# ESP32-H4 register map
Vendor: ESPRESSIF SYSTEMS (SHANGHAI) CO., LTD.; Series: ESP32 H-Series; File version: 1
CPU: RV32IMAC r0p0, little endian, no MPU, no FPU, 0 interrupt priority bits
Address unit: 32 bits
Registers are 32-bit, read-write, reset 0x0 unless marked. A register's access mark holds for its fields unless they carry their own. Offsets are from the block's base; [hi:lo] are bit positions; {n}, {i} and the like mark numbered series.

## HUK — HUK Peripheral
Base 0x600B1000
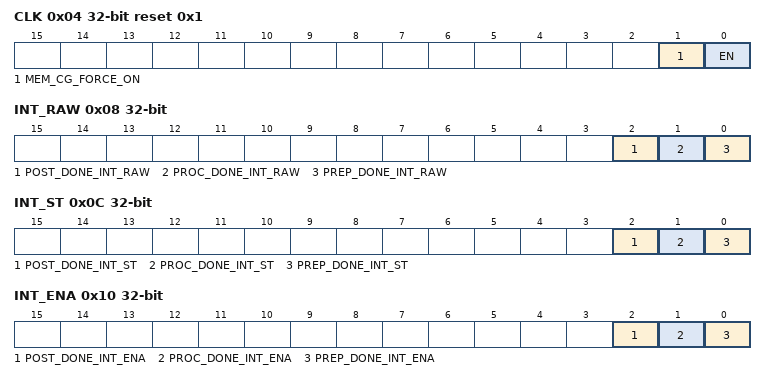
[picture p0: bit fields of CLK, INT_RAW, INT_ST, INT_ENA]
0x04 CLK reset 0x1 — HUK Generator clock gate control register
  [1] MEM_CG_FORCE_ON — Write 1 to force on memory clock gate.
  [0] EN — Write 1 to force on register clock gate.
0x08 INT_RAW ro — HUK Generator interrupt raw register, valid in level.
  [2] POST_DONE_INT_RAW — The raw interrupt status bit for the huk_post_done_int interrupt
  [1] PROC_DONE_INT_RAW — The raw interrupt status bit for the huk_proc_done_int interrupt
  [0] PREP_DONE_INT_RAW — The raw interrupt status bit for the huk_prep_done_int interrupt
0x0C INT_ST ro — HUK Generator interrupt status register.
  [2] POST_DONE_INT_ST — The masked interrupt status bit for the huk_post_done_int interrupt
  [1] PROC_DONE_INT_ST — The masked interrupt status bit for the huk_proc_done_int interrupt
  [0] PREP_DONE_INT_ST — The masked interrupt status bit for the huk_prep_done_int interrupt
0x10 INT_ENA — HUK Generator interrupt enable register.
  [2] POST_DONE_INT_ENA — The interrupt enable bit for the huk_post_done_int interrupt
  [1] PROC_DONE_INT_ENA — The interrupt enable bit for the huk_proc_done_int interrupt
  [0] PREP_DONE_INT_ENA — The interrupt enable bit for the huk_prep_done_int interrupt
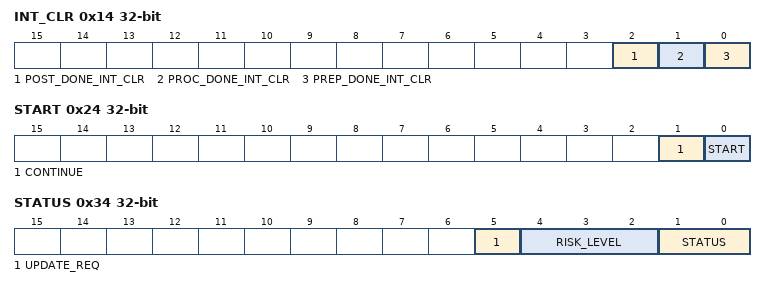
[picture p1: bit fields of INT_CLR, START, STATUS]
0x14 INT_CLR wo — HUK Generator interrupt clear register.
  [2] POST_DONE_INT_CLR — Set this bit to clear the huk_post_done_int interrupt
  [1] PROC_DONE_INT_CLR — Set this bit to clear the huk_proc_done_int interrupt
  [0] PREP_DONE_INT_CLR — Set this bit to clear the huk_prep_done_int interrupt
0x20 CONF — HUK Generator configuration register
  [0] MODE — Set this field to choose the huk process. 1: process huk generate mode. 0: process huk recovery mode.
0x24 START wo — HUK Generator control register
  [1] CONTINUE — Write 1 to start HUK Generator at IDLE state.
  [0] START — Write 1 to continue HUK Generator operation at LOAD/GAIN state.
0x28 STATE ro — HUK Generator state register
  [1:0] STATE — The state of HUK Generator. 0: IDLE. 1: LOAD. 2: GAIN. 3: BUSY.
0x34 STATUS ro — HUK Generator HUK status register
  [5] UPDATE_REQ — The update request of HUK info. 0: User can update HUK info according to the risk level. 1: The HUK info is expired, and user need to update it.
  [4:2] RISK_LEVEL — The risk level of HUK. 0-6: the higher the risk level is, the more error bits there are in the PUF SRAM. 7: Error Level, HUK is invalid.
  [1:0] STATUS — The HUK generation status. 0: HUK is not generated. 1: HUK is generated and valid. 2: HUK is generated but invalid. 3: reserved.
0xFC DATE reset 0x2404070 — Version control register
  [27:0] DATE — HUK Generator version control register.
{0x100+i} INFO_MEM[{i}] (i=0..383) 8-bit access not given — The memory that stores HUK info.

## INTPRI — INTPRI Peripheral
Base 0x60005000
{0x90+4i} CPU_INTR_FROM_CPU_{i} (i=0..3) — CPU_INTR_FROM_CPU_{i} mapping register
  [0] CPU_INTR_FROM_CPU — CPU_INTR_FROM_CPU_%s mapping register.
0xA0 DATE reset 0x2303150 — Version control register
  [27:0] DATE — Version control register.
0xA4 CLOCK_GATE reset 0x1 — register description
  [0] CLK_EN — Need add description
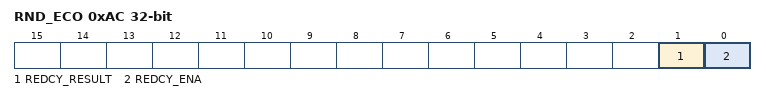
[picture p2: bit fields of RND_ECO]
0xAC RND_ECO access per field — redcy eco register.
  [1] REDCY_RESULT ro — Only reserved for ECO.
  [0] REDCY_ENA rw — Only reserved for ECO.
0xB0 RND_ECO_LOW — redcy eco low register.
  [31:0] REDCY_LOW — Only reserved for ECO.
0x3FC RND_ECO_HIGH reset 0xFFFFFFFF — redcy eco high register.
  [31:0] REDCY_HIGH — Only reserved for ECO.

## IO_MUX — Input/Output Multiplexer
Base 0x60092000
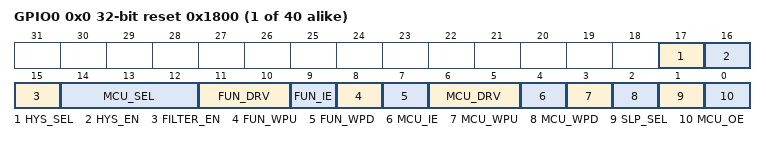
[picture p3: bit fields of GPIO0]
{0x0+4i} GPIO{i} (i=0..39) reset 0x1800 — IO MUX configuration register for GPIO{i}
  [17] HYS_SEL — Configures to choose the signal for enabling the hysteresis function for GPIO%s. \\ 0: Choose the output enable signal of eFuse\\ 1: Choose the output enable signal of IO_MUX_GPIO%s_HYS_EN\\
  [16] HYS_EN — Configures whether or not to enable the hysteresis function of the pin when IO_MUX_GPIO%s_HYS_SEL is set to 1.\\ 0: Disable\\ 1: Enable\\
  [15] FILTER_EN — Configures whether or not to enable filter for pin input signals.\\ 0: Disable\\ 1: Enable\\
  [14:12] MCU_SEL — Configures to select IO MUX function for this signal. \\ 0: Select Function 0\\ 1: Select Function 1\\ ......\\
  [11:10] FUN_DRV — Configures the drive strength of GPIO%s. \\ 0: ~5 mA\\ 1: ~10 mA\\ 2: ~20 mA\\ 3: ~40 mA\\
  [9] FUN_IE — Configures whether or not to enable input of GPIO%s.\\ 0: Disable\\ 1: Enable\\
  [8] FUN_WPU — Configures whether or not enable pull-up resistor of GPIO%s.\\ 0: Disable\\ 1: Enable\\
  [7] FUN_WPD — Configures whether or not to enable pull-down resistor of GPIO%s.\\ 0: Disable\\ 1: Enable\\
  [6:5] MCU_DRV — Configures the drive strength of GPIO%s during sleep mode. \\ 0: ~5 mA\\ 1: ~10 mA\\ 2: ~20 mA\\ 3: ~40 mA\\
  [4] MCU_IE — Configures whether or not to enable the input of GPIO%s during sleep mode.\\ 0: Disable\\ 1: Enable\\
  [3] MCU_WPU — Configures whether or not to enable pull-up resistor of GPIO%s during sleep mode. \\ 0: Disable\\ 1: Enable\\
  [2] MCU_WPD — Configure whether or not to enable pull-down resistor of GPIO%s in sleep mode.\\ 0: Disable\\ 1: Enable\\
  [1] SLP_SEL — Configures whether or not to enter sleep mode for GPIO%s.\\ 0: Not enter\\ 1: Enter\\
  [0] MCU_OE — Configures whether or not to enable the output of GPIO%s in sleep mode. 0: Disable\\ 1: Enable\\
0x1FC DATE reset 0x2412160 — Version control register
  [27:0] REG_DATE
